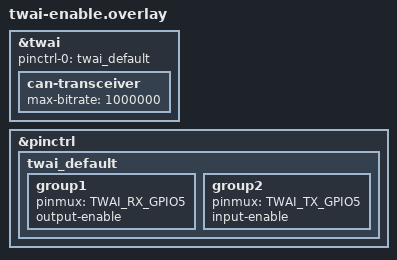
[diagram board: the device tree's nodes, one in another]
/*
 * Copyright (c) 2022 Martin Jäger <martin@libre.solar>
 *
 * SPDX-License-Identifier: Apache-2.0
 */

/* Enable CAN bus */
&twai {
	pinctrl-0 = <&twai_default>;
	pinctrl-names = "default";
	status = "okay";

	can-transceiver {
		max-bitrate = <1000000>;
	};
};

&pinctrl {
	twai_default: twai_default {
		group1 {
			pinmux = <TWAI_RX_GPIO5>;
			output-enable;	/* enable internal loopback */
		};

		group2 {
			pinmux = <TWAI_TX_GPIO5>;
			input-enable;	/* enable internal loopback */
		};
	};
};
